# YC3122 register map
Series: ARMCM0; File version: 1.0
CPU: CM0 r1p0, little endian, no MPU, no FPU, 8 interrupt priority bits
Registers are 32-bit, read-write, reset 0x0 unless marked. A register's access mark holds for its fields unless they carry their own. Offsets are from the block's base; [hi:lo] are bit positions; {n}, {i} and the like mark numbered series.

## MSEC
Base 0x000FAE00
0x00 LC
  [7:0] VAL — 仅支持比特置1操作,不支持清0回退 0x01: 上电非安全状态 其他值：用户自定义
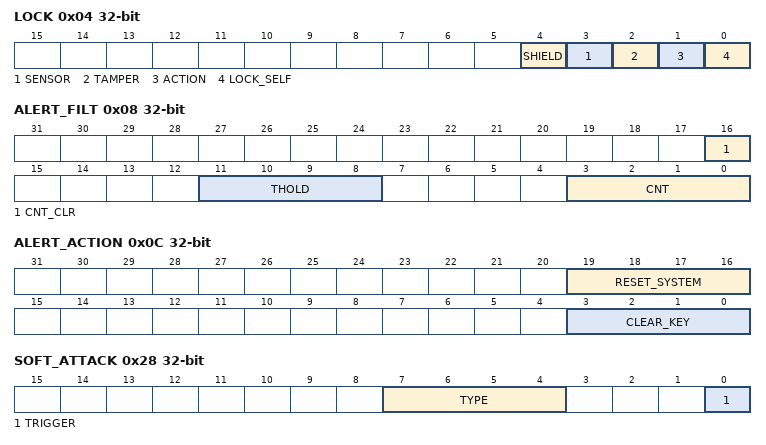
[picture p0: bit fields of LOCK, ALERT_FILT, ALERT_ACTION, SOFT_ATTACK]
0x04 LOCK
  [4] SHIELD — 1:锁定SHIELD_EN/SHIELD_CTR. L寄存器
  [3] SENSOR — 1:锁定SENSOR_EN/SENSOR_CTR. L/SENSOR_THRES寄存器
  [2] TAMPER — 1:锁定TAMP_EN/TAMP_CTRL/TA. MP_STA_CTRL/TAMP_DYN_CTRL寄存器
  [1] ACTION — 1:锁定 ALERT_ACTION寄存器
  [0] LOCK_SELF — 1:锁定LOCK寄存器本身(通常用于配置好其他的 锁定过后,且无法解锁)
0x08 ALERT_FILT
  [16] CNT_CLR wo — 写1 清除CNT寄存器的是值
  [11:8] THOLD — 当THOLD的配置大于等于CNT的值的时候会触发 ALERT_ACTION
  [3:0] CNT ro — 当TAMPER/SENSOR/SHIELD的报警 发生时cnt寄存器会加1
0x0C ALERT_ACTION
  [19:16] RESET_SYSTEM — 当ALERT_ACTION发生时,除了该寄存器配 置成0x5能失能复位系统动作,其他配置都会导致复位系统
  [3:0] CLEAR_KEY — 当ALERT_ACTION发生时,除了该寄存器配 置成0x5能失能清除秘钥动作,其他配置都会导致清除秘钥
0x20 SOFT_ATTACK_EN
  [0] EN — 置‘1’后无法清0. 1: 使能soft_attack功能
0x24 SOFT_ATTACK_LOCK
  [0] LOCK — 软件攻击锁定 0: 解锁 soft attack. 1: 锁定 soft attack 注：写此寄存器可置1和清0,写其他任意寄存器,此寄存器会 置1
0x28 SOFT_ATTACK
  [7:4] TYPE — soft_attack位检测到1时,锁存写数据的 比特7到4
  [0] TRIGGER wo — 写1触发软件攻击 注：必须先写soft_attack_lock为0,再写此 寄存器,中间不能插入其他寄存器读写操作
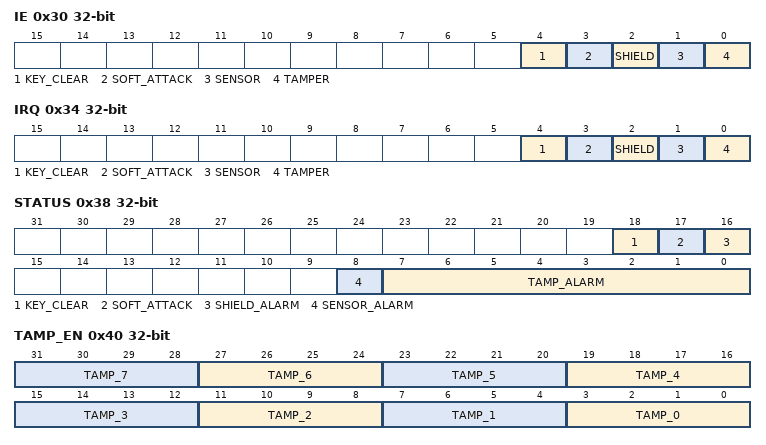
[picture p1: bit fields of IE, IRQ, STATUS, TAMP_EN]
0x30 IE
  [4] KEY_CLEAR — 1:使能清除秘钥触发中断
  [3] SOFT_ATTACK — 1:使能soft attact触发中断
  [2] SHIELD — 1:使能SHIELD触发中断
  [1] SENSOR — 1:使能SENSOR触发中断
  [0] TAMPER — 1:使能TAMPER触发中断
0x34 IRQ
  [4] KEY_CLEAR — 写‘1’清除KEY_CLEAR中断状态
  [3] SOFT_ATTACK — 写‘1’清除SOFT_ATTACK中断状态
  [2] SHIELD — 写‘1’清除SHIELD中断状态
  [1] SENSOR — 写‘1’清除SENSOR中断状态
  [0] TAMPER — 写‘1’清除TAMPER中断状态
0x38 STATUS
  [18] KEY_CLEAR ro — 清除秘钥中断状态
  [17] SOFT_ATTACK ro — 软件攻击中断状态
  [16] SHIELD_ALARM ro — SHIELD中断状态
  [8] SENSOR_ALARM ro — SENSOR中断状态
  [7:0] TAMP_ALARM ro — TAMPER中断状态,每1BIT代表一个TAMP. ER触发中断
0x40 TAMP_EN
  [4n+3:4n] TAMP_{n} (n=0..7) — TAMPER{n} 使能 0x5:使能 Others:使能
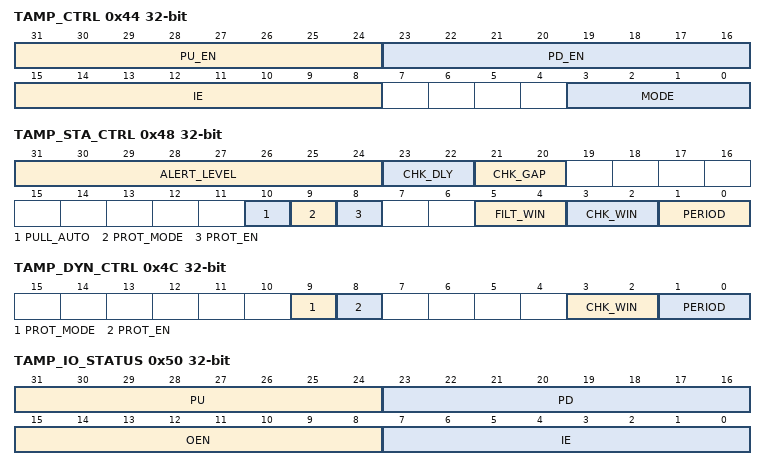
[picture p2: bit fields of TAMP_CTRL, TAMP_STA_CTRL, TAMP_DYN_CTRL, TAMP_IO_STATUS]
0x44 TAMP_CTRL
  [31:24] PU_EN — TAMPER IO上拉使能(每1BIT对应控制一 个 TAMPER IO) 动态模式:需要把输入脚上拉或下拉 静态模式:把对应IO上拉,PULL_AUTO为1时,自动 在静态检测期间使能上拉,其他时间禁止上拉,以减少功耗 注：Tamper IO 上电默认开启上拉,每个IO上拉或 下拉只能选择一个
  [23:16] PD_EN — TAMPER IO下拉使能(每1BIT对应控制一 个 TAMPER IO) 动态模式:需要把输入脚上拉或下拉 静态模式:把对应IO下拉,PULL_AUTO为1时,自动 在静态检测期间使能下拉,其他时间禁止下拉,以减少功耗
  [15:8] IE — TAMPER IO使能 动态模式,输入管脚需要使能IE,输出管脚不需要 静态模式,所有管脚均需要使能IE,PULL_AUTO为1 时,自动在静态检测期间使能IE,其他时间禁止IE,以减少 功耗
  [3:0] MODE — TAMPER IO模式(每1BIT控制两个IO, 按顺序对应IO0~7). 0:静态模式 1:动态模式
0x48 TAMP_STA_CTRL
  [31:24] ALERT_LEVEL — 分别对应8个引脚的静态报警电平 0: 低电平报警 1: 高电平报警
  [23:22] CHK_DLY — 静态上下拉开启后,延迟多长时间后进行检测 0: 1ms. 1: 4ms. 2: 8ms. 3: 16ms
  [21:20] CHK_GAP — 静态检测间隔 0: 1ms. 1: 2ms. 2: 4ms. 3: 8ms
  [10] PULL_AUTO — 0: 静态上下拉由软件控制 1: 静态上下拉只在配置工作期间有效,由硬件自动控制
  [9] PROT_MODE — 静态报警触发后,保护模式选择 0: 引脚处于高阻状态 1: 引脚自动上下拉（取决于外部电平）
  [8] PROT_EN — 静态报警触发后,IO是否启动自动保护 0: 不开启 ,继续进行检测 1: 开启 ,停止检测,进入保护模式,保护模式由PROT _MODE确定
  [5:4] FILT_WIN — 静态检测窗口报警过滤选择 0: 一个窗口检测到报警即为报警 1: 连续两个窗口检测到报警即为报警 2: 连续三个窗口检测到报警即为报警 3: 连续四个窗口检测到报警即为报警
  [3:2] CHK_WIN — 窗口内采样过滤选择 0: 窗口内进行一次采样,一次采样成功即触发窗口报警 1: 窗口内进行两次采样,连续两次采样成功即触发窗口报警 2: 窗口内进行三次采样,连续三次采样成功即触发窗口报警 3: 窗口内进行四次采样,连续四次采样成功即触发窗口报警
  [1:0] PERIOD — 静态检测周期 0: 32ms. 1: 125ms. 2: 500ms. 3: 0.9999s
0x4C TAMP_DYN_CTRL
  [9] PROT_MODE — 动态报警触发后,保护模式选择 0: 引脚处于高阻状态 1: 引脚自动上下拉（取决于外部电平）
  [8] PROT_EN — 动态报警触发后,IO是否启动自动保护 0: 不开启 1: 开启 ,保护模式由PROT_MODE确定
  [3:2] CHK_WIN — 窗口内采样过滤选择 0: 窗口内进行一次采样,一次采样成功即触发窗口报警 1: 窗口内进行两次采样,连续两次采样成功即触发窗口报警 2: 窗口内进行三次采样,连续三次采样成功即触发窗口报警 3: 窗口内进行四次采样,连续四次采样成功即触发窗口报警
  [1:0] PERIOD — 动态检测周期 0: 32ms. 1: 125ms. 2: 500ms. 3: 0.9999s
0x50 TAMP_IO_STATUS
  [31:24] PU ro — IO上拉状态
  [23:16] PD ro — IO下拉状态
  [15:8] OEN ro — IO使能状态
  [7:0] IE ro — IO IE状态
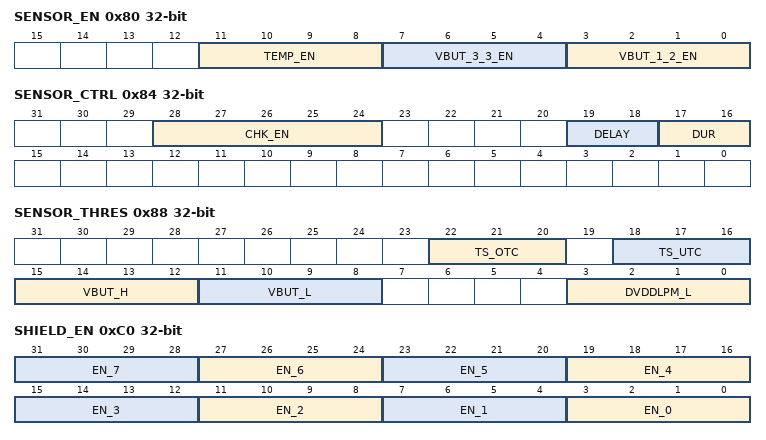
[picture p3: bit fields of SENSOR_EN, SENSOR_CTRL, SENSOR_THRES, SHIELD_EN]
0x80 SENSOR_EN
  [11:8] TEMP_EN — 温度传感器使能: 0x5:失能 Others:使能
  [7:4] VBUT_3_3_EN — 纽扣电池3.3V输入电压传感器使能: 0x5:失能 Others:使能
  [3:0] VBUT_1_2_EN — 纽扣电池1.2V输出电压传感器使能: 0x5:失能 Others:使能
0x84 SENSOR_CTRL
  [28:24] CHK_EN — 传感器检测使能 [4]: 低温检测使能 [3]: 高温检测使能 [2]: 纽扣电池3.3v输出低压检测使能 [1]: 纽扣电池3.3v输出高压检测使能 [0]: 纽扣电池1.2v输出低压检测使能
  [19:18] DELAY — 警报持续时间门限,大于门限的信号,将触发报警。用 于滤除毛刺,防止虚警。 00: 1*(1/32k)=31.25us. 01: 8*(1/32k)=250us. 10: 32*(1/32k)=1ms. 11: 128*(1/32k)=4ms 注：这个时间必须小于sensor_duration时间
  [17:16] DUR — Sensor检测时间长度。 00: always on. 01: 2ms. 10: 8ms. 11: 16ms
0x88 SENSOR_THRES
  [22:20] TS_OTC — 高温报警温度设置 0: 85. 1: 90. 2: 95. 3: 100. 4: 105
  [18:16] TS_UTC — 低温报警温度设置 0: -40. 1: -35. 2: -30. 3: -25. 4: -20
  [15:12] VBUT_H — 纽扣电池3.3V输入电压高报警设置 0000: 3.471. 0001: 3.577. 0010: 3.690. 0011: 3.810. 0100: 3.938. 0101: 4.076. 0110: 4.223. 0111: 4.381. 1000: 4.552. 1001: 4.736. 1010: 4.936. 1011: 5.154. 1100: 5.392. 1101: 5.653. 1110: 5.926. 1111: 6.115
  [11:8] VBUT_L — 纽扣电池3.3V输入电压低报警设置 0000: 1.938. 0001: 1.971. 0010: 2.005. 0011: 2.040. 0100: 2.076. 0101: 2.113. 0110: 2.152. 0111: 2.193. 1000: 2.235. 1001: 2.278. 1010: 2.324. 1011: 2.371. 1100: 2.420. 1101: 2.471. 1110: 2.525. 1111: 2.580
  [3:0] DVDDLPM_L — 纽扣电池1.2V输出电压低报警设置 报警值等于 0.83+DVDDLPM_L*0.02
0xC0 SHIELD_EN
  [4n+3:4n] EN_{n} (n=0..7) — SHIELD {n}使能 0x5 :失能 Others: 使能
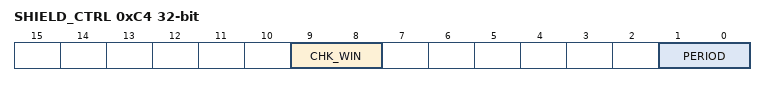
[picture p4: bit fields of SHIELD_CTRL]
0xC4 SHIELD_CTRL
  [9:8] CHK_WIN — 窗口内采样过滤选择 0: 窗口内进行一次采样,一次采样成功即触发窗口报警 1: 窗口内进行两次采样,连续两次采样成功即触发窗口报警 2: 窗口内进行三次采样,连续三次采样成功即触发窗口报警 3: 窗口内进行四次采样,连续四次采样成功即触发窗口报警
  [1:0] PERIOD — Shield工作周期 0: 32ms. 1: 125ms. 2: 500ms. 3: 0.9999s
